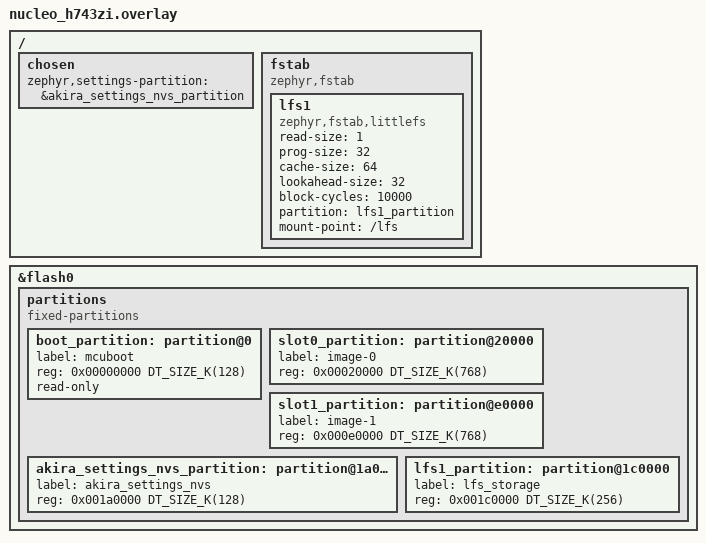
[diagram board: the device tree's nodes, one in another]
/*
 * ST Nucleo-H743ZI DTS overlay for AkiraOS
 * Board: nucleo_h743zi
 *
 * The upstream nucleo_h743zi board in Zephyr already defines:
 *   - USART3 on PD8/PD9 (console), ETH, SPI1/2/4/5, I2C1/2/4,
 *     ADC1/3, TIM1/2/3/4/5, USB OTG FS, SDMMC1, QSPI
 *
 * This overlay adds AkiraOS-specific flash partitioning.
 * STM32H743ZI: 2 MB dual-bank flash (bank1: 0x08000000, bank2: 0x08100000)
 */

/*
 * STM32H743 flash: 2 MB, 128 KB sectors. The upstream board already defines a
 * partition table under &flash0 (boot/storage/slot0@40000/slot1/scratch), so
 * delete those nodes first — otherwise our labels collide with theirs (the
 * duplicate slot0_partition was the build error). Then lay AkiraOS out on
 * 128 KB (sector) boundaries, which the H7 flash driver requires for erase.
 * AkiraOS builds MCUboot images, so keep equal slot0/slot1 (768 KB each) for
 * A/B DFU, then settings-NVS + LittleFS in the remaining sectors.
 */
/delete-node/ &boot_partition;
/delete-node/ &storage_partition;
/delete-node/ &slot0_partition;
/delete-node/ &slot1_partition;
/delete-node/ &scratch_partition;

&flash0 {
    partitions {
        compatible = "fixed-partitions";
        #address-cells = <1>;
        #size-cells = <1>;

        boot_partition: partition@0 {
            label = "mcuboot";
            reg = <0x00000000 DT_SIZE_K(128)>;
            read-only;
        };

        slot0_partition: partition@20000 {
            label = "image-0";
            reg = <0x00020000 DT_SIZE_K(768)>;
        };

        slot1_partition: partition@e0000 {
            label = "image-1";
            reg = <0x000e0000 DT_SIZE_K(768)>;
        };

        akira_settings_nvs_partition: partition@1a0000 {
            label = "akira_settings_nvs";
            reg = <0x001a0000 DT_SIZE_K(128)>;
        };

        lfs1_partition: partition@1c0000 {
            label = "lfs_storage";
            reg = <0x001c0000 DT_SIZE_K(256)>;
        };
    };
};

/ {
    chosen {
        zephyr,settings-partition = &akira_settings_nvs_partition;
    };

    fstab {
        compatible = "zephyr,fstab";

        lfs1: lfs1 {
            compatible = "zephyr,fstab,littlefs";
            read-size = <1>;
            prog-size = <32>;
            cache-size = <64>;
            lookahead-size = <32>;
            block-cycles = <10000>;
            partition = <&lfs1_partition>;
            mount-point = "/lfs";
        };
    };
};
